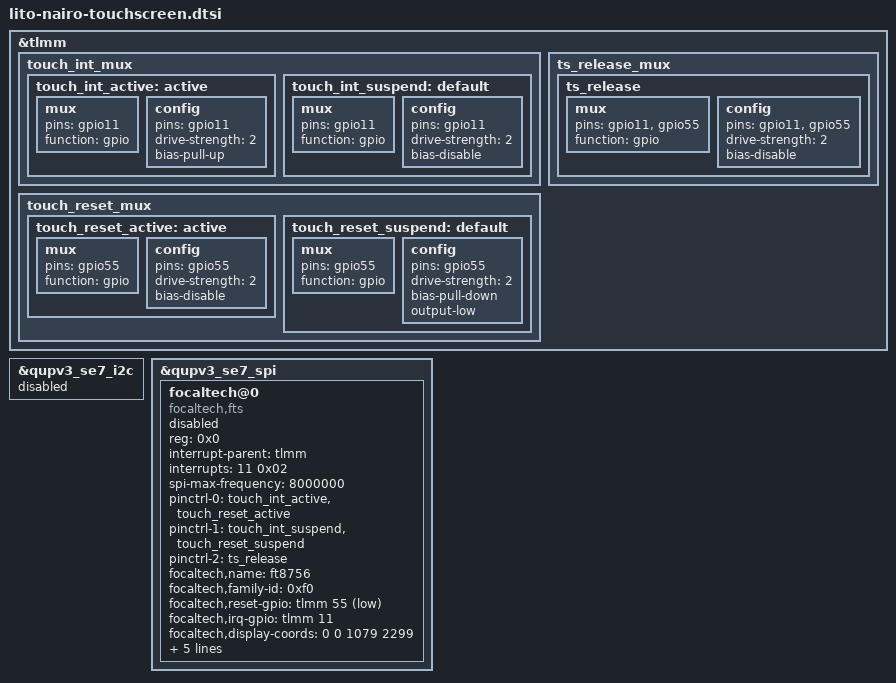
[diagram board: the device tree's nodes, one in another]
&tlmm {
	touch_int_mux {
		touch_int_active: active {
			mux {
				pins = "gpio11";
				function = "gpio";
			};
			config {
				pins = "gpio11";
				drive-strength = <2>;
				bias-pull-up;
			};
		};

		touch_int_suspend: default {
			mux {
				pins = "gpio11";
				function = "gpio";
			};
			config {
				pins = "gpio11";
				drive-strength = <2>;
				bias-disable;
			};
		};
	};

	touch_reset_mux {
		touch_reset_active: active {
			mux {
				pins = "gpio55";
				function = "gpio";
			};
			config {
				pins = "gpio55";
				drive-strength = <2>;
				bias-disable;
			};
		};

		touch_reset_suspend: default {
			mux {
				pins = "gpio55";
				function = "gpio";
			};
			config {
				pins = "gpio55";
				drive-strength = <2>;
				bias-pull-down;
				output-low;
			};
		};
	};

	ts_release_mux {
		ts_release: ts_release {
			mux {
				pins = "gpio11", "gpio55";
				function = "gpio";
			};

			config {
				pins = "gpio11", "gpio55";
				drive-strength = <2>;
				bias-disable;
			};
		};
	};
};

&qupv3_se7_i2c {
	status = "disabled";
};

&qupv3_se7_spi {
	status = "ok";
	focaltech@0 {
		compatible = "focaltech,fts";
		reg = <0x0>;
		interrupt-parent = <&tlmm>;
		interrupts = <11 0x02>;
		spi-max-frequency=<8000000>;
		pinctrl-names = "pmx_ts_active","pmx_ts_suspend","pmx_ts_release";
		pinctrl-0 = <&touch_int_active &touch_reset_active>;
		pinctrl-1 = <&touch_int_suspend &touch_reset_suspend>;
		pinctrl-2 = <&ts_release>;
		focaltech,name = "ft8756";
		focaltech,family-id = <0xf0>;
		focaltech,reset-gpio = <&tlmm 55 0x01>;
		focaltech,irq-gpio = <&tlmm 11 0x02>;
		focaltech,display-coords = <0 0 1079 2299>;
		focaltech,max-touch-number = <10>;
		focaltech,panel-supplier = "tianma";
		focaltech,always_on_vio;
		focaltech,dlfw_in_resume;
		focaltech,report_gesture_key;
		status = "/chosen", "mmi,panel_name", "tm_ft8756_636_1080x2300_vid";
	};
};
